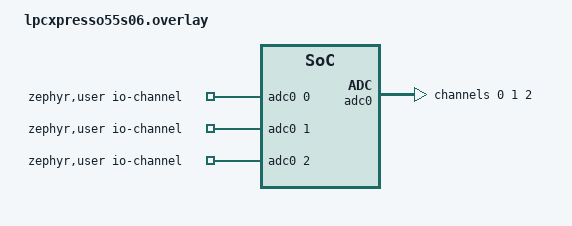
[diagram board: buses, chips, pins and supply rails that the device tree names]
/*
 * SPDX-FileCopyrightText: Copyright 2026 NXP
 * SPDX-License-Identifier: Apache-2.0
 */

#include <zephyr/dt-bindings/adc/adc.h>
#include <zephyr/dt-bindings/adc/mcux-lpadc.h>

/ {
	zephyr,user {
		io-channels = <&adc0 0>, <&adc0 1>, <&adc0 2>;
	};
};

&adc0 {
	#address-cells = <1>;
	#size-cells = <0>;

	/* CH8A is internal ground, expect ~0 mV */
	channel@0 {
		reg = <0>;
		zephyr,gain = "ADC_GAIN_1";
		zephyr,reference = "ADC_REF_EXTERNAL0";
		zephyr,vref-mv = <3300>;
		zephyr,acquisition-time = <ADC_ACQ_TIME_DEFAULT>;
		zephyr,resolution = <12>;
		zephyr,input-positive = <MCUX_LPADC_CH8A>;
	};

	/* CH13A is the internal bandgap reference, expect ~930 mV */
	channel@1 {
		reg = <1>;
		zephyr,gain = "ADC_GAIN_1";
		zephyr,reference = "ADC_REF_EXTERNAL0";
		zephyr,vref-mv = <3300>;
		zephyr,acquisition-time = <ADC_ACQ_TIME_DEFAULT>;
		zephyr,resolution = <16>;
		zephyr,input-positive = <MCUX_LPADC_CH13A>;
	};

	/* CH12A is internal VDDA, expect ~3300 mV */
	channel@2 {
		reg = <2>;
		zephyr,gain = "ADC_GAIN_1";
		zephyr,reference = "ADC_REF_EXTERNAL0";
		zephyr,vref-mv = <3300>;
		zephyr,acquisition-time = <ADC_ACQ_TIME_DEFAULT>;
		zephyr,resolution = <12>;
		zephyr,input-positive = <MCUX_LPADC_CH12A>;
	};
};
